VERSION ""

NS_ :

BS_:
BU_: Gopro
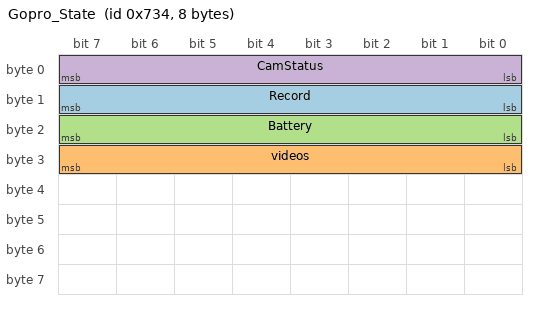
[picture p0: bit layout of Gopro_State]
BO_ 1844 Gopro_State: 8 Gopro
   SG_ Record : 15|8@0+ (1,0) [0|1] "" Vector__XXX
   SG_ videos : 31|8@0+ (1,0) [0|1] "" Vector__XXX
   SG_ Battery : 23|8@0+ (1,0) [0|1] "" Gopro
   SG_ CamStatus : 7|8@0+ (1,0) [0|1] "" Gopro

BA_DEF_ BO_ "GenMsgBackgroundColor" STRING ;
BA_DEF_ BO_ "GenMsgForegroundColor" STRING ;
BA_DEF_ BO_ "filterlabeling" INT 0 0;
BA_DEF_DEF_ "GenMsgBackgroundColor" "#242424";
BA_DEF_DEF_ "GenMsgForegroundColor" "#f0f0f0";
BA_DEF_DEF_ "filterlabeling" 1;
